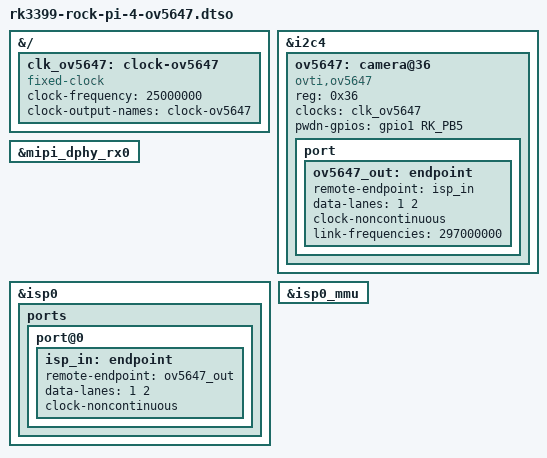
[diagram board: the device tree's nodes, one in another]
// SPDX-License-Identifier: (GPL-2.0+ OR MIT)
/*
 * Copyright 2022 Ideas on Board Oy
 *
 * Overlay for Raspberry Pi OV5647 camera module connected to the Rock Pi 4
 */

/dts-v1/;
/plugin/;

#include <dt-bindings/gpio/gpio.h>
#include <dt-bindings/pinctrl/rockchip.h>

&{/} {
	clk_ov5647: clock-ov5647 {
		compatible = "fixed-clock";
		#clock-cells = <0>;
		clock-frequency = <25000000>;
		clock-output-names = "clock-ov5647";
	};
};

&i2c4 {
	ov5647: camera@36 {
		compatible = "ovti,ov5647";
		reg = <0x36>;

		clocks = <&clk_ov5647>;
		pwdn-gpios = <&gpio1 RK_PB5 GPIO_ACTIVE_HIGH>;

		port {
			ov5647_out: endpoint {
				remote-endpoint = <&isp_in>;
				data-lanes = <1 2>;
				clock-noncontinuous;
				link-frequencies = /bits/ 64 <297000000>;
			};
		};
	};
};

&mipi_dphy_rx0 {
	status = "okay";
};

&isp0 {
	status = "okay";

	ports {
		port@0 {
			isp_in: endpoint {
				remote-endpoint = <&ov5647_out>;
				data-lanes = <1 2>;
				clock-noncontinuous;
			};
		};
	};
};

&isp0_mmu {
	status = "okay";
};
